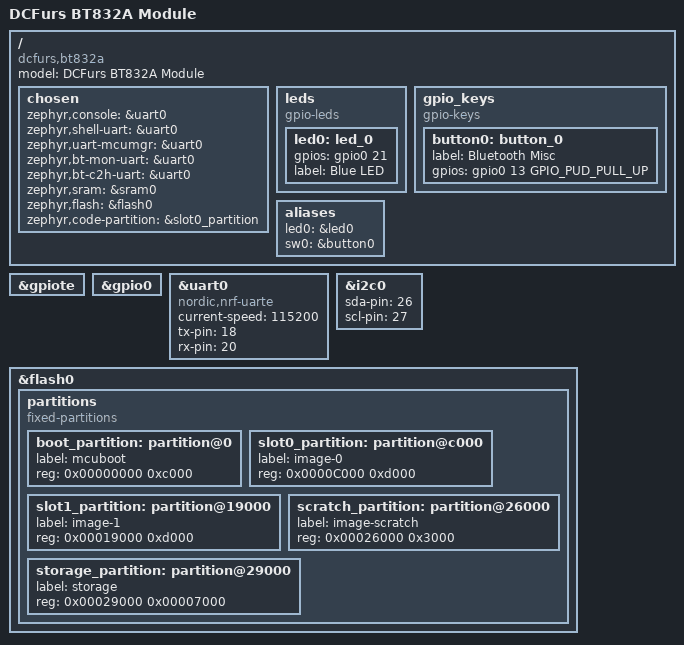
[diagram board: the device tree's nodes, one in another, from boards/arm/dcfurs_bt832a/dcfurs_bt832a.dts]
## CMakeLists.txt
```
# SPDX-License-Identifier: Apache-2.0

cmake_minimum_required(VERSION 3.13.1)
set(BOARD dcfurs_bt832a)
set(BOARD_ROOT ${CMAKE_CURRENT_SOURCE_DIR})
add_definitions(-DNRFX_TWIS_ENABLED=1 -DNRFX_TWIS0_ENABLED=1)
include($ENV{ZEPHYR_BASE}/cmake/app/boilerplate.cmake NO_POLICY_SCOPE)
project(badge)

FILE(GLOB app_sources src/*.c)
target_sources(app PRIVATE ${app_sources})

zephyr_library_include_directories($ENV{ZEPHYR_BASE}/samples/bluetooth)
```

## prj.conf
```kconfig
CONFIG_BT=y
CONFIG_BT_BROADCASTER=y
CONFIG_BT_OBSERVER=y
CONFIG_BT_DEBUG_LOG=y
CONFIG_CONSOLE_SUBSYS=y
CONFIG_CONSOLE_GETLINE=y
CONFIG_DYNAMIC_INTERRUPTS=y
CONFIG_HWINFO=y
CONFIG_NEWLIB_LIBC=y
```

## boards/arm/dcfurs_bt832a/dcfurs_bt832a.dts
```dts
/*
 * Copyright (c) 2018 Nordic Semiconductor ASA
 * Copyright (c) 2017 Shawn Nock <shawn@monadnock.ca>
 * Copyright (c) 2017 Linaro Limited
 *
 * SPDX-License-Identifier: Apache-2.0
 */

/dts-v1/;
#include <nordic/nrf52810_qfaa.dtsi>

/ {
	model = "DCFurs BT832A Module";
	compatible = "dcfurs,bt832a", "fanstel,bt832a",
		"nordic,nrf52810-qfaa", "nordic,nrf52810";

	chosen {
		zephyr,console = &uart0;
		zephyr,shell-uart = &uart0;
		zephyr,uart-mcumgr = &uart0;
		zephyr,bt-mon-uart = &uart0;
		zephyr,bt-c2h-uart = &uart0;
		zephyr,sram = &sram0;
		zephyr,flash = &flash0;
		zephyr,code-partition = &slot0_partition;
	};

	leds {
		compatible = "gpio-leds";
		led0: led_0 {
			gpios = <&gpio0 21 GPIO_INT_ACTIVE_HIGH>;
			label = "Blue LED";
		};
	};

	gpio_keys {
		compatible = "gpio-keys";
		button0: button_0 {
			label = "Bluetooth Misc";
			gpios = <&gpio0 13 GPIO_PUD_PULL_UP>;
		};
	};

	/* These aliases are provided for compatibility with samples */
	aliases {
		led0 = &led0;
		sw0 = &button0;
	};
};

&gpiote {
	status = "okay";
};

&gpio0 {
	status = "okay";
};

&uart0 {
	status = "okay";
	compatible = "nordic,nrf-uarte";
	current-speed = <115200>;
	tx-pin = <18>;
	rx-pin = <20>;
};

&i2c0 {
	status = "okay";
	sda-pin = <26>;
	scl-pin = <27>;
};

&flash0 {
	/*
	 * For more information, see:
	 * http://docs.zephyrproject.org/latest/guides/dts/index.html#flash-partitions
	 */
	partitions {
		compatible = "fixed-partitions";
		#address-cells = <1>;
		#size-cells = <1>;

		boot_partition: partition@0 {
			label = "mcuboot";
			reg = <0x00000000 0xc000>;
		};
		slot0_partition: partition@c000 {
			label = "image-0";
			reg = <0x0000C000 0xd000>;
		};
		slot1_partition: partition@19000 {
			label = "image-1";
			reg = <0x00019000 0xd000>;
		};
		scratch_partition: partition@26000 {
			label = "image-scratch";
			reg = <0x00026000 0x3000>;
		};
		storage_partition: partition@29000 {
			label = "storage";
			reg = <0x00029000 0x00007000>;
		};
	};
};
```

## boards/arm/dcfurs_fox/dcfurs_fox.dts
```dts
/*
 * Copyright (c) 2019 DEFCON Furs
 *
 * SPDX-License-Identifier: Apache-2.0
 */

/dts-v1/;
#include <nordic/nrf52832_qfaa.dtsi>

/ {
	model = "DCFurs Fox Beacon";
	compatible = "dcfurs,fox", "fanstel,bt832",
		"nordic,nrf52832-qfaa", "nordic,nrf52832";

	chosen {
		zephyr,console = &uart0;
		zephyr,shell-uart = &uart0;
		zephyr,uart-mcumgr = &uart0;
		zephyr,bt-mon-uart = &uart0;
		zephyr,bt-c2h-uart = &uart0;
		zephyr,sram = &sram0;
		zephyr,flash = &flash0;
		zephyr,code-partition = &slot0_partition;
	};

	leds {
		compatible = "gpio-leds";
		led0: led_0 {
			gpios = <&gpio0 21 GPIO_INT_ACTIVE_HIGH>;
			label = "Blue LED";
		};
	};

	gpio_keys {
		compatible = "gpio-keys";
		button0: button_0 {
			label = "Bluetooth Misc";
			gpios = <&gpio0 13 GPIO_PUD_PULL_UP>;
		};
	};

	/* These aliases are provided for compatibility with samples */
	aliases {
		led0 = &led0;
		sw0 = &button0;
	};
};

&gpiote {
	status = "okay";
};

&gpio0 {
	status = "okay";
};

&uart0 {
	status = "okay";
	compatible = "nordic,nrf-uart";
	current-speed = <115200>;
	tx-pin = <18>;
	rx-pin = <20>;
};

&i2c0 {
	status = "okay";
	sda-pin = <26>;
	scl-pin = <27>;
};

&flash0 {
	/*
	 * For more information, see:
	 * http://docs.zephyrproject.org/latest/guides/dts/index.html#flash-partitions
	 */
	partitions {
		compatible = "fixed-partitions";
		#address-cells = <1>;
		#size-cells = <1>;

		boot_partition: partition@0 {
			label = "mcuboot";
			reg = <0x00000000 0xc000>;
		};
		slot0_partition: partition@c000 {
			label = "image-0";
			reg = <0x0000C000 0x32000>;
		};
		slot1_partition: partition@3e000 {
			label = "image-1";
			reg = <0x0003E000 0x32000>;
		};
		scratch_partition: partition@70000 {
			label = "image-scratch";
			reg = <0x00070000 0xa000>;
		};
		storage_partition: partition@7a000 {
			label = "storage";
			reg = <0x0007a000 0x00006000>;
		};
	};
};
```

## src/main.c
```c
/* main.c - Application main entry point */

/*
 * Copyright (c) 2019 DEFCON Furs
 *
 * SPDX-License-Identifier: Apache-2.0
 */

#include <zephyr/types.h>
#include <stddef.h>
#include <string.h>
#include <stdio.h>
#include <stdlib.h>
#include <misc/printk.h>
#include <misc/util.h>
#include <drivers/hwinfo.h>
#include <kernel.h>
#include <console.h>
#include <sys/crc.h>

#include <bluetooth/bluetooth.h>
#include <bluetooth/hci.h>

/* For UICR/Rabies tag programming */
#include <nrf.h>
#include <system_nrf51.h>

#include "badge.h"

static void
do_set(int argc, char **argv)
{
    int i;
    for (i = 0; i < argc; i++) {
        /* In case the value is optional. */
        char *name = argv[i];
        char *value = strchr(argv[i], '=');
        if (value) *value++ = '\0';

        if (strcmp(name, "cooldown") == 0) {
            //dc27_emote_cooldown = strtoul(value, NULL, 0);
            //dc27_emote_reset_cooldowns();
        }
        if (strcmp(name, "serial") == 0) {
            dc27_i2c_regs.status.serial = strtoul(value, NULL, 0);
            dc27_beacon_refresh();
        }
    }
}

static void
do_tx(int argc, char **argv)
{
    int i;
     for (i = 0; i < argc; i++) {
        /* In case the value is optional. */
        char *name = argv[i];
        char *value = strchr(argv[i], '=');
        if (value) *value++ = '\0';

        if (strcmp(name, "awoo") == 0) {
            //dc27_awoo_cooldown = k_uptime_get() + K_SECONDS(300);
            //dc27_start_awoo(64, dc27_i2c_status.serial);
        }
    }
}

static void
do_echo(int argc, char **argv)
{
    int i;
    printk("echo:");
    for (i = 0; i < argc; i++) {
        printk(" %s", argv[i]);
    }
            printk("\n");
}

void
main(void)
{
    int err;

    /* Setup the initial state of the I2C register space. */
    hwinfo_get_device_id(dc27_i2c_regs.status.devid, sizeof(dc27_i2c_regs.status.devid));
    strcpy(dc27_i2c_regs.config.name, "DEFCON Furs");

    console_getline_init();
    i2c_slave_init(&dc27_i2c_regs);

    printk("Starting DC27 Badge Comms\n");
    err = dc26_beacon_init();
    if (err) {
        printk("Bluetooth init failed (err %d)\n", err);
        return;
    }

    /* Run the console to handle input from the host. */
    while (1) {
        char *s = console_getline();
        char *name;
        char *args[16];
        int i;

        /* Each line shouold conform to the sytax action: name=value ... */
        name = strtok(s, ":");
        if (!name) {
            continue;
        }
        for (i = 0; i < sizeof(args)/sizeof(args[0]); i++) {
            args[i] = strtok(NULL, " ");
            if (!args[i]) break;
        }
        /* Some functions that we might care to run. */
        if (strcmp(name, "echo") == 0) {
            do_echo(i, args);
        }
        else if (strcmp(name, "set") == 0) {
            do_set(i, args);
            dc27_beacon_refresh();
        }
        else if (strcmp(name, "tx") == 0) {
            do_tx(i, args);
        }
    }
}
```

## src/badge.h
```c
#ifndef DCFURS_INCLUDE_BADGE_H_
#define DCFURS_INCLUDE_BADGE_H_

#include <sys/types.h>
#include <stdint.h>

/* Status registers we export via I2C. */
struct i2c_regs {
    /* Status Registers - treated as read-only. */
    struct {
        /* Static identifiers */
        uint8_t     devid[8];
        uint16_t    serial;
        /* Dynamic data received via BLE */
        uint8_t     magic;      /* Outgoing magic byte. */
        uint8_t     flags;      /* DC27_FLAG_xxxx */
        uint16_t    color;      /* Suggested color point (rgb565). */
        uint16_t    duration;   /* Suggested color duration (msec). */
        int8_t      rssi;       /* Average beacon RSSI. */
        uint8_t     ttl;        /* TTL for routed messages. */
        uint16_t    origin;     /* Originator for current messages. */
        uint8_t     emote[8];   /* Received emote string. */
    } status;

    /* Config Registers - treated as read-write. */
    struct {
        char        name[16];   /* BLE advertisement name */
    } config;
};

/* Status Register Flags */
#define DC27_FLAG_EMOTE     (1 << 0)

/* #badgelife/DCFurs beacon constants */
#define DC27_MAGIC_NONE     0x00
#define DC27_MAGIC_AWOO     0xa0
#define DC27_MAGIC_EMOTE    0xb2
#define DC27_MAGIC_COLOR    0xc3
#define DC27_APPEARANCE     0x27dc
#define DCFURS_MFGID_BADGE  0x71ff
#define DCFURS_MFGID_BEACON 0x0DCF

void dc27_beacon_refresh(void);
void dc27_start_awoo(uint8_t ttl, uint16_t origin);
int dc26_beacon_init(void);
int i2c_slave_init(struct i2c_regs *regs);

extern struct i2c_regs dc27_i2c_regs;

#endif /* DCFURS_INCLUDE_BADGE_H_ */
```

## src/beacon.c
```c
#include <zephyr/types.h>
#include <stddef.h>
#include <string.h>
#include <stdio.h>
#include <stdlib.h>
#include <misc/printk.h>
#include <misc/util.h>
#include <drivers/hwinfo.h>
#include <kernel.h>
#include <console.h>
#include <sys/crc.h>
#include <nrf.h>

#include <bluetooth/bluetooth.h>
#include <bluetooth/hci.h>

#include "badge.h"

struct i2c_regs dc27_i2c_regs;

static void dc27_magic_expire(struct k_timer *timer_id);
K_TIMER_DEFINE(dc27_magic_timer, dc27_magic_expire, NULL);
static void dc27_emote_expire(struct k_timer *timer_id);
K_TIMER_DEFINE(dc27_emote_timer, dc27_emote_expire, NULL);

/* Timer/Workqueue handlers for updating beacon contents. */
static void dc27_beacon_reset(struct k_work *work)
{
    struct i2c_regs *regs = &dc27_i2c_regs;
    struct bt_le_adv_param adv_param = {
        .options = 0,
        .interval_min = BT_GAP_ADV_SLOW_INT_MIN,
        .interval_max = BT_GAP_ADV_SLOW_INT_MAX,
    };
    u8_t adv_length = 0;
    u8_t adv_data[32];

    /* Stop advertising and update the beacon payload. */
    bt_le_adv_stop();

    /* Fixed #badgelife header format */
    adv_data[adv_length++] = (DCFURS_MFGID_BADGE >> 0) & 0xff;
    adv_data[adv_length++] = (DCFURS_MFGID_BADGE >> 8) & 0xff;
    adv_data[adv_length++] = regs->status.magic;
    adv_data[adv_length++] = (regs->status.serial >> 0) & 0xff;
    adv_data[adv_length++] = (regs->status.serial >> 8) & 0xff;

    /*
     * For any magic beacons, set the advertising rate as fast as possible, and
     * schedule a timer to disable the magic after one second. 
     */
    if (regs->status.magic != DC27_MAGIC_NONE) {
        adv_param.interval_min = BT_GAP_ADV_FAST_INT_MIN_1;
        adv_param.interval_max = BT_GAP_ADV_FAST_INT_MAX_1;
        k_timer_start(&dc27_magic_timer, K_SECONDS(1), 0);
    }

    /* Add any additional beacon contents depending on the magic byte. */
    switch (regs->status.magic) {
        case DC27_MAGIC_AWOO:
            /* Stop propagation when TTL reaches zero. */
            if (regs->status.ttl == 0) return;
            adv_data[adv_length++] = regs->status.ttl - 1;
            adv_data[adv_length++] = (regs->status.origin >> 0) & 0xff;
            adv_data[adv_length++] = (regs->status.origin >> 8) & 0xff;
            break;
        
        case DC27_MAGIC_EMOTE:
            adv_data[adv_length++] = (regs->status.color >> 0) & 0xff;
            adv_data[adv_length++] = (regs->status.color >> 8) & 0xff;
            strncpy(adv_data + adv_length, regs->status.emote, sizeof(regs->status.emote));
            adv_length += strnlen(regs->status.emote, sizeof(regs->status.emote));
            break;
        
        case DC27_MAGIC_COLOR:
            adv_data[adv_length++] = (regs->status.color >> 0) & 0xff;
            adv_data[adv_length++] = (regs->status.color >> 8) & 0xff;
            adv_data[adv_length++] = (regs->status.duration >> 0) & 0xff;
            adv_data[adv_length++] = (regs->status.duration >> 8) & 0xff;
            break;
    }

    /* Start the advertisement. */
    /* TODO: If the adv_data got too long, we may need to use active scan data. */
    struct bt_data adv[] = {
        BT_DATA_BYTES(BT_DATA_GAP_APPEARANCE, (DC27_APPEARANCE & 0x00ff) >> 0, (DC27_APPEARANCE & 0xff00) >> 8),
        BT_DATA_BYTES(BT_DATA_FLAGS, BT_LE_AD_GENERAL | BT_LE_AD_NO_BREDR),
        BT_DATA(BT_DATA_NAME_COMPLETE, regs->config.name, strnlen(regs->config.name, sizeof(regs->config.name))),
        BT_DATA(BT_DATA_MANUFACTURER_DATA, adv_data, adv_length),
    };
    bt_le_adv_start(&adv_param, adv, ARRAY_SIZE(adv), NULL, 0);
}
K_WORK_DEFINE(dc27_beacon_worker, dc27_beacon_reset);

static void do_transmit(struct k_work *work)
{
    struct i2c_regs *regs = &dc27_i2c_regs;
    struct bt_le_adv_param adv_param = {
        .options = 0,
        .interval_min = BT_GAP_ADV_FAST_INT_MIN_1,
        .interval_max = BT_GAP_ADV_FAST_INT_MAX_1,
    };
    u8_t i;
    u8_t adv_length = 0;
    u8_t adv_data[32];

    /* Stop advertising and update the beacon payload. */
    bt_le_adv_stop();
    /* Start a timer to reset the beacon after 1 second. */
    k_timer_start(&dc27_magic_timer, K_SECONDS(1), 0);

    /* Fixed #badgelife header format */
    adv_data[adv_length++] = (DCFURS_MFGID_BADGE >> 0) & 0xff;
    adv_data[adv_length++] = (DCFURS_MFGID_BADGE >> 8) & 0xff;
    adv_data[adv_length++] = regs->config.txmagic;
    adv_data[adv_length++] = (regs->status.serial >> 0) & 0xff;
    adv_data[adv_length++] = (regs->status.serial >> 8) & 0xff;
    /* Copy in the arbitrary payload data. */
    for (i = 0; i < regs->config.txlen; i++) {
        if (adv_length >= sizeof(adv_data)) break;
        adv_data[adv_length++] = regs->config.txdata[i];
    }

    /* Start the advertisement. */
    struct bt_data adv[] = {
        BT_DATA_BYTES(BT_DATA_GAP_APPEARANCE, (DC27_APPEARANCE & 0x00ff) >> 0, (DC27_APPEARANCE & 0xff00) >> 8),
        BT_DATA_BYTES(BT_DATA_FLAGS, BT_LE_AD_GENERAL | BT_LE_AD_NO_BREDR),
        BT_DATA(BT_DATA_NAME_COMPLETE, regs->config.name, strnlen(regs->config.name, sizeof(regs->config.name))),
        BT_DATA(BT_DATA_MANUFACTURER_DATA, adv_data, adv_length),
    };
    bt_le_adv_start(&adv_param, adv, ARRAY_SIZE(adv), NULL, 0);
}
K_WORK_DEFINE(dc27_transmit_worker, do_transmit);

/* Timer function to clear out any magic beacons. */
static void dc27_magic_expire(struct k_timer *timer_id)
{
    dc27_i2c_regs.status.magic = DC27_MAGIC_NONE;
    k_work_submit(&dc27_beacon_worker);
}

/* Timer function to clear out any emotes and color suggestions. */
static void dc27_emote_expire(struct k_timer *timer_id)
{
    dc27_i2c_regs.status.color = 0;
    dc27_i2c_regs.status.duration = 0;
    dc27_i2c_regs.status.flags &= ~DC27_FLAG_EMOTE;
    memset(dc27_i2c_regs.status.emote, 0, sizeof(dc27_i2c_regs.status.emote));
}

/* Called when the beacon contents need to be refreshed. */
void dc27_beacon_refresh(void)
{
    k_work_submit(&dc27_beacon_worker);
}

/* Called to begin an arbitrary beacon transmit via the I2C regs. */
void dc27_start_transmit(void)
{
    k_work_submit(&dc27_transmit_worker);
}

/* Average RSSI Tracking */
#define DC27_RSSI_INIT			-80
#define DC27_RSSI_HISTORY_LEN	512
static s32_t dc27_rssi_sum = DC27_RSSI_INIT * DC27_RSSI_HISTORY_LEN;

/* Return the average RSSI */
static s8_t dc27_rssi_average(void)
{
    return dc27_rssi_sum / DC27_RSSI_HISTORY_LEN;
}

/* Update the average RSSI */
static void dc27_rssi_insert(s8_t rssi)
{
    static unsigned int idx = 0;
    static s8_t history[DC27_RSSI_HISTORY_LEN] = {
        [0 ... (DC27_RSSI_HISTORY_LEN-1)] = DC27_RSSI_INIT
	};

    /* Update the RSSI history. */
    s8_t prev = history[idx];
    history[idx] = rssi;
    idx = (idx + 1) % DC27_RSSI_HISTORY_LEN;

    /* Update the sum */
    dc27_rssi_sum -= prev;
    dc27_rssi_sum += rssi;

    /* Update the exported RSSI measurement. */
    dc27_i2c_regs.status.rssi = dc27_rssi_sum / DC27_RSSI_HISTORY_LEN;
}

/* Cooldown timer between emotes. */
static s64_t dc27_emote_cooldown = 60000;
static s64_t dc27_emote_short_cooldown = 0;     /* For beacons with very high RSSI */
static s64_t dc27_emote_medium_cooldown = 0;    /* For beacons with average RSSI */
static s64_t dc27_emote_long_cooldown = 0;      /* For beacons with very weak RSSI */
static s64_t dc27_awoo_cooldown = 0;            /* For beacons starting a howl */

static s64_t dc27_emote_jitter(unsigned int max)
{
    return (max/2) + sys_rand32_get() % (max/2);
}

static void dc27_emote_reset_cooldowns(void)
{
    s64_t now = k_uptime_get();
    dc27_emote_short_cooldown = now + dc27_emote_jitter(dc27_emote_cooldown);
    dc27_emote_medium_cooldown = now + dc27_emote_jitter(dc27_emote_cooldown << 1);
    dc27_emote_long_cooldown = now + dc27_emote_jitter(dc27_emote_cooldown << 2);
}

static unsigned int dc27_emote_test_cooldowns(s8_t rssi)
{
    s64_t now = k_uptime_get();
    if (((rssi + 10) < dc27_rssi_average()) && (dc27_emote_long_cooldown > now)) {
        /* Beacon is 10dB below the average RSSI, and the long cooldown has not elapsed. */
        return 0; /* Long cooldown has not elapsed */
    }
    if ((rssi < -75) && (dc27_emote_medium_cooldown > now)) {
        return 0; /* Medium cooldown has not elapsed */
    }
    if (dc27_emote_short_cooldown > now) {
        return 0; /* Short cooldown has not elapsed */
    }

    /* Reset the cooldowns */
    dc27_emote_reset_cooldowns();
    return 1;
}

#if 0
/* bloom filter of blacklisted addresses */
static uint8_t 	dc27_blacklist[1024 / 8];

static void dc27_blacklist_insert(const bt_addr_le_t *addr)
{
    uint16_t ansi = crc16_ansi(addr->a.val, sizeof(addr->a.val));
    uint16_t ccitt = crc16_ccitt(addr->a.val, sizeof(addr->a.val));
    dc27_blacklist[(ansi >> 3) % sizeof(dc27_blacklist)] |= (1 << (ansi & 0x7));
    dc27_blacklist[(ccitt >> 3) % sizeof(dc27_blacklist)] |= (1 << (ccitt & 0x7));
}

static void dc27_blacklist_check(const bt_addr_le_t *addr)
{
    uint16_t ansi = crc16_ansi(addr->a.val, sizeof(addr->a.val));
    uint16_t ccitt = crc16_ccitt(addr->a.val, sizeof(addr->a.val));
    return (dc27_blacklist[(ansi >> 3) % sizeof(dc27_blacklist)] & (1 << (ansi & 0x7)) && 
            dc27_blacklist[(ccitt >> 3) % sizeof(dc27_blacklist)] & (1 << (ccitt & 0x7)));
}
#endif

struct dc27_scan_data {
    char name[32];
    uint16_t appearance;
    uint16_t mfgid;
    uint16_t serial;
    uint8_t magic;
    uint8_t length;
    uint8_t payload[16];
};

static bool dc27_scan_parse(struct bt_data *ad, void *user_data)
{
    struct dc27_scan_data *scan = (struct dc27_scan_data *)user_data;

    switch (ad->type) {
        case BT_DATA_GAP_APPEARANCE:
            if (ad->data_len != 2) {
                scan->appearance = 0xffff;
                return false;
            }
            scan->appearance = (ad->data[1] << 8) | ad->data[0];
            break;
		
        case BT_DATA_NAME_COMPLETE:
        case BT_DATA_NAME_SHORTENED:
            if (ad->data_len >= sizeof(scan->name)) {
                scan->appearance = 0xffff;
                return false;
            }
            memcpy(scan->name, ad->data, ad->data_len);
            scan->name[ad->data_len] = '\0';
            break;
		
        case BT_DATA_MANUFACTURER_DATA:
            if (ad->data_len < 3) {
                scan->appearance = 0xffff;
                return false;
            }
            scan->mfgid = (ad->data[1] << 8) | ad->data[0];
            scan->magic = ad->data[2];
            if (ad->data_len >= 5) {
                scan->serial = (ad->data[3] << 8) | ad->data[4];
            }
            if (ad->data_len > 5) {
                scan->length = ad->data_len - 5;
                if (scan->length >= sizeof(scan->payload)) {
                    scan->length = sizeof(scan->payload);
                }
                memcpy(scan->payload, &ad->data[5], scan->length);
            }
            break;
    }
    return true;
}

static void scan_cb(const bt_addr_le_t *addr, s8_t rssi, u8_t adv_type,
                    struct net_buf_simple *buf)
{
    char src[BT_ADDR_LE_STR_LEN];
    struct dc27_scan_data data;

    /* Parse the BLE advertisemnet. */
    memset(&data, 0, sizeof(data));
    bt_data_parse(buf, dc27_scan_parse, &data);
    if (data.appearance != DC27_APPEARANCE) {
        /* Not a part of this year's convention. */
        return;
    }

    dc27_rssi_insert(rssi);
    bt_addr_le_to_str(addr, src, sizeof(src));
    
    /* Handle special beacons. */
    switch (data.magic) {
        case DC27_MAGIC_EMOTE:
            if (!dc27_emote_test_cooldowns(rssi)) break;
            if (data.length < 2) break;
            dc27_i2c_regs.status.color = (data.payload[1] << 8) | data.payload[0];
            dc27_i2c_regs.status.flags |= DC27_FLAG_EMOTE;
            /* TODO: Parse the desired emote. */
            memset(dc27_i2c_regs.status.emote, 0, sizeof(dc27_i2c_regs.status.emote));
            k_timer_start(&dc27_emote_timer, K_SECONDS(5), 0);
            break;
        
        case DC27_MAGIC_COLOR:
            /* Only accept color suggestion from DCFurs beacons.  */
            /* TODO: Do we want any signing or obfuscation to prevent abuse? */
            /* A cooldown would prevent coordinated lighting effects. */
            if (data.mfgid != DCFURS_MFGID_BEACON) break;
            if (data.length < 4) break;
            else {
                /* Require at least 500ms for color suggestion. */
                uint16_t duration = (data.payload[3] << 8) | data.payload[2];
                if (duration < 500) duration = 500;
                dc27_i2c_regs.status.duration = duration;
                dc27_i2c_regs.status.color = (data.payload[1] << 8) | data.payload[0];
                k_timer_start(&dc27_emote_timer, duration, 0);
            }
            break;
        
        case DC27_MAGIC_AWOO:
            /* Filter out unwanted awoo's */
            if (data.mfgid != DCFURS_MFGID_BADGE) break;
            if (dc27_awoo_cooldown > k_uptime_get()) break;
            if (data.length < 3) break;

            /* Route the magic beacon another hop */
            dc27_awoo_cooldown = k_uptime_get() + K_SECONDS(300);
            dc27_i2c_regs.status.magic = DC27_MAGIC_AWOO;
            dc27_i2c_regs.status.ttl = data.payload[0];
            dc27_i2c_regs.status.origin = (data.payload[2] << 8) | data.payload[1];
            dc27_beacon_refresh();
            break;
    }

#if 0
    printk("rx: mfgid=0x%02x rssi=%d avg=%d magic=%02x\n", data.mfgid, rssi, dc27_rssi_average(), data.magic);
#endif
}

int dc26_beacon_init(void)
{
    struct bt_le_scan_param scan_param = {
        .type       = BT_HCI_LE_SCAN_PASSIVE,
        .filter_dup = BT_HCI_LE_SCAN_FILTER_DUP_DISABLE,
        .interval   = 0x0010,
        .window     = 0x0010,
    };

    /* Initialize the Bluetooth Subsystem */
    int err = bt_enable(NULL);
    if (err) return err;

    err = bt_le_scan_start(&scan_param, scan_cb);
    if (err) {
        printk("Starting scanning failed (err %d)\n", err);
        return err;
    }

    /* Start advertising */
    dc27_emote_reset_cooldowns();
    dc27_beacon_refresh();

    /* Success */
    return 0;
}
```

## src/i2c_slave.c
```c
/*
 * Copyright (c) 2018, Nordic Semiconductor ASA
 *
 * SPDX-License-Identifier: Apache-2.0
 */
#include <drivers/i2c.h>
#include <dt-bindings/i2c/i2c.h>
#include <nrfx_twis.h>

#include "badge.h"

#define LOG_DOMAIN "i2c_nrfx_twis"
#define LOG_LEVEL CONFIG_I2C_LOG_LEVEL
#include <logging/log.h>
LOG_MODULE_REGISTER(i2c_nrfx_twis);

#define I2C_REGADDR_TEXT 64

struct i2c_dcfurs_data {
    nrfx_twis_t twis;
    nrfx_twis_config_t config;
    /* Register data */
    struct i2c_regs *regs;
    const char      *text;
    size_t          text_length;
    /* Pretend to operate as an I2C EEPROM with 8-bit addressing. */
    uint8_t  bufaddr;
    uint8_t  buffer[256];
};

/* I2C slave hardware configuration. */
static struct i2c_dcfurs_data i2c_data = {
    .twis = NRFX_TWIS_INSTANCE(0),
    .config = {
        .addr     = {0x42, 0},
        .scl      = DT_NORDIC_NRF_I2C_I2C_0_SCL_PIN,
        .sda      = DT_NORDIC_NRF_I2C_I2C_0_SDA_PIN,
        .scl_pull = NRF_GPIO_PIN_NOPULL,
        .sda_pull = NRF_GPIO_PIN_NOPULL,
        .interrupt_priority = NRFX_TWIS_DEFAULT_CONFIG_IRQ_PRIORITY,
    },
    .bufaddr = 0,
    .buffer = {0},
};

/* Fill up the read buffer. */
static void fill_buffer(struct i2c_dcfurs_data *data)
{
    const uint8_t *indata = (const void *)data->regs;
    int in = data->bufaddr;
    int out = 0;

    /* Get bytes from the register map */
    while (in < sizeof(struct i2c_regs)) {
        data->buffer[out++] = indata[in++];
    }

    /* Get bytes from the test region. */
    while (in < I2C_REGADDR_TEXT) {
        data->buffer[out++] = 0x00;
        in++;
    }
    while ((in - I2C_REGADDR_TEXT) < data->text_length) {
        if (out >= sizeof(data->buffer)) return;
        data->buffer[out++] = data->text[in - I2C_REGADDR_TEXT];
        in++;
    }
    while (out < sizeof(data->buffer)) {
        data->buffer[out++] = 0;
    }
}

/* Handle any writes to the rw section. */
static void flush_write(struct i2c_dcfurs_data *data, uint32_t length)
{
    uint8_t *outdata = (void *)&data->regs;
    int out = data->bufaddr;
    int in = 0;
    int end;

    /* Require at least one byte for the address, and at least one payload byte. */
    if (length < 2) return;
    length--;
    if (length > sizeof(data->buffer)) length = sizeof(data->buffer);
    end = data->bufaddr + length;

    /* Skip any bytes in the RO registers. */
    if (out < offsetof(struct i2c_regs, config)) {
        in += (offsetof(struct i2c_regs, config) - out);
        out = offsetof(struct i2c_regs, config);
    }
    /* Ignore any bytes passed the end of the RW registers. */
    if (end > sizeof(struct i2c_regs)) {
        end = sizeof(struct i2c_regs);
    }
    if (in >= end) return;

    /* Any remaining bytes must be in the RW registers, so copy them. */
    while (in < end) {
        outdata[out++] = data->buffer[in++];
    }
    /* Signal that the beacon may need to be reset. */
    dc27_beacon_refresh();
}

static void event_handler(nrfx_twis_evt_t const *p_event)
{
    struct i2c_dcfurs_data *data = &i2c_data;

	switch (p_event->type) {
	case NRFX_TWIS_EVT_READ_REQ:
        /* Read requested - setup the transmit buffer. */
        fill_buffer(data);
        nrfx_twis_tx_prepare(&data->twis, &data->buffer, sizeof(data->buffer));
        break;

	case NRFX_TWIS_EVT_READ_DONE:
        /* Advance the buffer address by the number of bytes read. */
        data->bufaddr += p_event->data.tx_amount;
        break;
        
	case NRFX_TWIS_EVT_WRITE_REQ:
        /* Write requested - setup the receive buffer for both the payload and the address. */
        data->bufaddr = 0;
        nrfx_twis_rx_prepare(&data->twis, &data->bufaddr, sizeof(data->bufaddr) + sizeof(data->buffer));
        break;
    
    case NRFX_TWIS_EVT_WRITE_DONE:
        /* Write completed - examine the address and copy the data out to its final home. */
        flush_write(data, p_event->data.rx_amount);
        if (p_event->data.rx_amount) {
            data->bufaddr += p_event->data.rx_amount - 1;
        }
        break;

	case NRFX_TWIS_EVT_READ_ERROR:
    case NRFX_TWIS_EVT_WRITE_ERROR:
    case NRFX_TWIS_EVT_GENERAL_ERROR:
    default:
        /* Data overrun of some kind occurred. */
		break;
	}
}

/* Attach and start I2C as an slave */
int i2c_slave_init(struct i2c_regs *regs)
{
    struct i2c_dcfurs_data *data = &i2c_data;
	nrfx_err_t result;

    i2c_data.regs = regs;
    i2c_data.text = "Hello World!";
    i2c_data.text_length = strlen(i2c_data.text);

    IRQ_CONNECT(DT_NORDIC_NRF_I2C_I2C_0_IRQ_0,
            DT_NORDIC_NRF_I2C_I2C_0_IRQ_0_PRIORITY,
            nrfx_isr, nrfx_twis_0_irq_handler, 0);
                
    result = nrfx_twis_init(&data->twis, &data->config, event_handler);
	if (result != NRFX_SUCCESS) {
		LOG_ERR("Failed to initialize i2c slave device");
		return -EBUSY;
	}
	nrfx_twis_enable(&data->twis);

	return 0;
}
```
